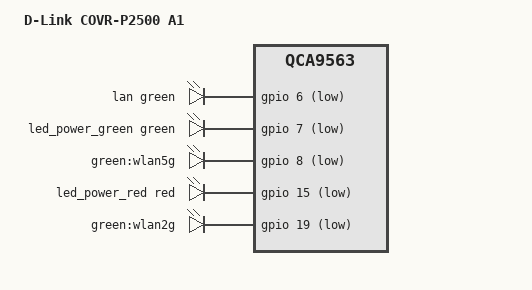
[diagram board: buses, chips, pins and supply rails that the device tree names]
// SPDX-License-Identifier: GPL-2.0-or-later OR MIT

#include "qca9563_dlink_covr.dtsi"

/ {
	compatible = "dlink,covr-p2500-a1", "qca,qca9563";
	model = "D-Link COVR-P2500 A1";

	aliases {
		led-boot = &led_power_green;
		led-failsafe = &led_power_red;
		led-running = &led_power_green;
		led-upgrade = &led_power_red;
	};

	leds {
		compatible = "gpio-leds";
		pinctrl-names = "default";
		pinctrl-0 = <&jtag_disable_pins>;

		lan {
			function = LED_FUNCTION_LAN;
			color = <LED_COLOR_ID_GREEN>;
			gpios = <&gpio 6 GPIO_ACTIVE_LOW>;
		};

		led_power_green: power_green {
			function = LED_FUNCTION_POWER;
			color = <LED_COLOR_ID_GREEN>;
			gpios = <&gpio 7 GPIO_ACTIVE_LOW>;
			default-state = "on";
		};

		wlan5g {
			label = "green:wlan5g";
			gpios = <&gpio 8 GPIO_ACTIVE_LOW>;
			linux,default-trigger = "phy0radio";
		};

		led_power_red: power_red {
			function = LED_FUNCTION_POWER;
			color = <LED_COLOR_ID_RED>;
			gpios = <&gpio 15 GPIO_ACTIVE_LOW>;
		};

		wlan2g {
			label = "green:wlan2g";
			gpios = <&gpio 19 GPIO_ACTIVE_LOW>;
			linux,default-trigger = "phy1radio";
		};
	};
};
